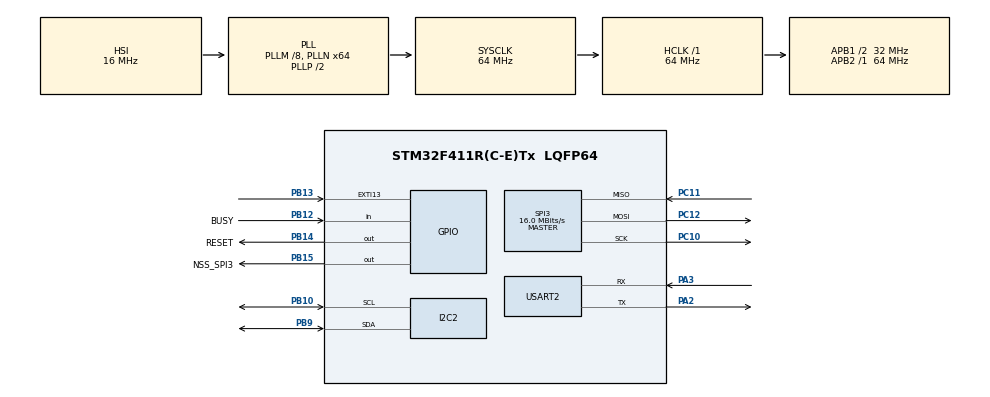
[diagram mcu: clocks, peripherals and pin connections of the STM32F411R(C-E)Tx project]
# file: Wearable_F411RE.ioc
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FREERTOS.Tasks01=defaultTask,24,128,StartDefaultTask,Default,NULL,Dynamic,NULL,NULL
FREERTOS.configENABLE_FPU=1
FREERTOS.configUSE_IDLE_HOOK=1
I2C2.OwnAddress=104
Mcu.Family=STM32F4
Mcu.Name=STM32F411R(C-E)Tx
Mcu.Package=LQFP64
NVIC.EXTI15_10_IRQn=true\:5\:0\:false\:false\:true\:true\:true\:true\:true
NVIC.PriorityGroup=NVIC_PRIORITYGROUP_4
NVIC.TIM2_IRQn=true\:15\:0\:false\:false\:true\:false\:false\:true\:true
NVIC.TimeBase=TIM2_IRQn
NVIC.TimeBaseIP=TIM2
PA13.GPIO_Label=TMS
PA13.Mode=Serial_Wire
PA13.Signal=SYS_JTMS-SWDIO
PA14.GPIO_Label=TCK
PA14.Mode=Serial_Wire
PA14.Signal=SYS_JTCK-SWCLK
PA2.Mode=Asynchronous
PA2.Signal=USART2_TX
PA3.Mode=Asynchronous
PA3.Signal=USART2_RX
PB10.Mode=I2C
PB10.Signal=I2C2_SCL
PB12.GPIO_Label=BUSY
PB12.Signal=GPIO_Input
PB13.Signal=GPXTI13
PB14.GPIO_Label=RESET
PB14.Signal=GPIO_Output
PB15.GPIO_Label=NSS_SPI3
PB15.Signal=GPIO_Output
PB3.GPIO_Label=SWO
PB3.Signal=SYS_JTDO-SWO
PB9.Mode=I2C
PB9.Signal=I2C2_SDA
PC10.Mode=Full_Duplex_Master
PC10.Signal=SPI3_SCK
PC11.Mode=Full_Duplex_Master
PC11.Signal=SPI3_MISO
PC12.Mode=Full_Duplex_Master
PC12.Signal=SPI3_MOSI
PC14-OSC32_IN.Mode=LSE-External-Oscillator
PC14-OSC32_IN.Signal=RCC_OSC32_IN
PC15-OSC32_OUT.Mode=LSE-External-Oscillator
PC15-OSC32_OUT.Signal=RCC_OSC32_OUT
PH0\ -\ OSC_IN.Mode=HSE-External-Oscillator
PH0\ -\ OSC_IN.Signal=RCC_OSC_IN
PH1\ -\ OSC_OUT.Mode=HSE-External-Oscillator
PH1\ -\ OSC_OUT.Signal=RCC_OSC_OUT
ProjectManager.HeapSize=0x200
ProjectManager.StackSize=0x400
ProjectManager.TargetToolchain=CMake
RCC.48MHZClocksFreq_Value=32000000
RCC.AHBFreq_Value=64000000
RCC.APB1CLKDivider=RCC_HCLK_DIV2
RCC.APB1Freq_Value=32000000
RCC.APB1TimFreq_Value=64000000
RCC.APB2Freq_Value=64000000
RCC.APB2TimFreq_Value=64000000
RCC.CortexFreq_Value=64000000
RCC.FLatency-AdvancedSettings=FLASH_LATENCY_2
RCC.HCLKFreq_Value=64000000
RCC.HSE_VALUE=8000000
RCC.HSI_VALUE=16000000
RCC.PLLM=8
RCC.PLLN=64
RCC.SYSCLKFreq_VALUE=64000000
RCC.SYSCLKSource=RCC_SYSCLKSOURCE_PLLCLK
RCC.VCOOutputFreq_Value=128000000
SPI3.CalculateBaudRate=16.0 MBits/s
SPI3.Direction=SPI_DIRECTION_2LINES
SPI3.Mode=SPI_MODE_MASTER
SPI3.VirtualType=VM_MASTER
TIM1.Prescaler=83
USART2.VirtualMode=VM_ASYNC
VP_FREERTOS_VS_CMSIS_V2.Mode=CMSIS_V2
VP_SYS_VS_tim2.Mode=TIM2
VP_TIM1_VS_ClockSourceINT.Mode=Internal
VP_TIM1_VS_ClockSourceITR.Mode=TriggerSource_ITR0
VP_TIM1_VS_ControllerModeReset.Mode=Reset Mode
board=NUCLEO-F411RE

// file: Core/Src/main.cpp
/* USER CODE BEGIN Header */
/**
 ******************************************************************************
 * @file           : main.c
 * @brief          : Main program body
 ******************************************************************************
 * @attention
 *
 * Copyright (c) 2025 STMicroelectronics.
 * All rights reserved.
 *
 * This software is licensed under terms that can be found in the LICENSE file
 * in the root directory of this software component.
 * If no LICENSE file comes with this software, it is provided AS-IS.
 *
 ******************************************************************************
 */
/* USER CODE END Header */
#include "main.h"
#include "cmsis_os.h"

/* USER CODE BEGIN Includes */
#include "RadioLib.h"
#include "SX1261.h"
#include "stm32RadioHal.h"
#include "LoRa.h"
#include "quaternion.h"
#include "compute_direction.h"
/* USER CODE END Includes */

I2C_HandleTypeDef hi2c2;

SPI_HandleTypeDef hspi3;

TIM_HandleTypeDef htim1;

UART_HandleTypeDef huart2;

/* Definitions for defaultTask */
osThreadId_t defaultTaskHandle;
const osThreadAttr_t defaultTask_attributes = {
    .name = "defaultTask",
    .stack_size = 128 * 4,
    .priority = (osPriority_t)osPriorityNormal,
};
/* USER CODE BEGIN PV */
SemaphoreHandle_t Transmit_receive_mutex = NULL;
/* USER CODE END PV */

void SystemClock_Config(void);
static void MX_GPIO_Init(void);
static void MX_SPI3_Init(void);
static void MX_I2C2_Init(void);
static void MX_TIM1_Init(void);
static void MX_USART2_UART_Init(void);
void StartDefaultTask(void *argument);

int main(void)
{

  /* MCU Configuration--------------------------------------------------------*/

  /* Reset of all peripherals, Initializes the Flash interface and the Systick. */
  HAL_Init();

  /* Configure the system clock */
  SystemClock_Config();

  /* Initialize all configured peripherals */
  MX_GPIO_Init();
  MX_SPI3_Init();
  MX_I2C2_Init();
  MX_TIM1_Init();
  MX_USART2_UART_Init();
  /* USER CODE BEGIN 2 */
  IMU_init();
  IMU_Calibrate_Accel_Gyro();
  IMU_Calibrate_Mag();
  set_yaw_offset();
  LoRa_Init();
  // Start the quaternion example task

  /* USER CODE END 2 */

  /* Init scheduler */
  osKernelInitialize();

  /* Create the thread(s) */
  /* creation of defaultTask */
  /* USER CODE BEGIN RTOS_THREADS */
  /* add threads, ... */
  xTaskCreate(LoRa_Calibrate_RSSI_rx, "LoRa_Calibrate_RSSI_rx", 512, NULL, 1, NULL);
  // xTaskCreate(LoRa_Calibrate_RSSI_tx, "LoRa_Calibrate_RSSI_tx", 512, NULL, 1, NULL);
  /* USER CODE END RTOS_THREADS */

  /* Start scheduler */
  osKernelStart();

  /* We should never get here as control is now taken by the scheduler */

  /* Infinite loop */
  while (1)
  {

  }
}

void SystemClock_Config(void)
{
  RCC_OscInitTypeDef RCC_OscInitStruct = {0};
  RCC_ClkInitTypeDef RCC_ClkInitStruct = {0};

  /** Configure the main internal regulator output voltage
   */
  __HAL_RCC_PWR_CLK_ENABLE();
  __HAL_PWR_VOLTAGESCALING_CONFIG(PWR_REGULATOR_VOLTAGE_SCALE1);

  /** Initializes the RCC Oscillators according to the specified parameters
   * in the RCC_OscInitTypeDef structure.
   */
  RCC_OscInitStruct.OscillatorType = RCC_OSCILLATORTYPE_HSI;
  RCC_OscInitStruct.HSIState = RCC_HSI_ON;
  RCC_OscInitStruct.HSICalibrationValue = RCC_HSICALIBRATION_DEFAULT;
  RCC_OscInitStruct.PLL.PLLState = RCC_PLL_ON;
  RCC_OscInitStruct.PLL.PLLSource = RCC_PLLSOURCE_HSI;
  RCC_OscInitStruct.PLL.PLLM = 8;
  RCC_OscInitStruct.PLL.PLLN = 64;
  RCC_OscInitStruct.PLL.PLLP = RCC_PLLP_DIV2;
  RCC_OscInitStruct.PLL.PLLQ = 4;
  if (HAL_RCC_OscConfig(&RCC_OscInitStruct) != HAL_OK)
  {
    Error_Handler();
  }

  /** Initializes the CPU, AHB and APB buses clocks
   */
  RCC_ClkInitStruct.ClockType = RCC_CLOCKTYPE_HCLK | RCC_CLOCKTYPE_SYSCLK | RCC_CLOCKTYPE_PCLK1 | RCC_CLOCKTYPE_PCLK2;
  RCC_ClkInitStruct.SYSCLKSource = RCC_SYSCLKSOURCE_PLLCLK;
  RCC_ClkInitStruct.AHBCLKDivider = RCC_SYSCLK_DIV1;
  RCC_ClkInitStruct.APB1CLKDivider = RCC_HCLK_DIV2;
  RCC_ClkInitStruct.APB2CLKDivider = RCC_HCLK_DIV1;

  if (HAL_RCC_ClockConfig(&RCC_ClkInitStruct, FLASH_LATENCY_2) != HAL_OK)
  {
    Error_Handler();
  }
}

static void MX_I2C2_Init(void)
{

  hi2c2.Instance = I2C2;
  hi2c2.Init.ClockSpeed = 100000;
  hi2c2.Init.DutyCycle = I2C_DUTYCYCLE_2;
  hi2c2.Init.OwnAddress1 = 208;
  hi2c2.Init.AddressingMode = I2C_ADDRESSINGMODE_7BIT;
  hi2c2.Init.DualAddressMode = I2C_DUALADDRESS_DISABLE;
  hi2c2.Init.OwnAddress2 = 0;
  hi2c2.Init.GeneralCallMode = I2C_GENERALCALL_DISABLE;
  hi2c2.Init.NoStretchMode = I2C_NOSTRETCH_DISABLE;
  if (HAL_I2C_Init(&hi2c2) != HAL_OK)
  {
    Error_Handler();
  }
}

static void MX_SPI3_Init(void)
{

  /* SPI3 parameter configuration*/
  hspi3.Instance = SPI3;
  hspi3.Init.Mode = SPI_MODE_MASTER;
  hspi3.Init.Direction = SPI_DIRECTION_2LINES;
  hspi3.Init.DataSize = SPI_DATASIZE_8BIT;
  hspi3.Init.CLKPolarity = SPI_POLARITY_LOW;
  hspi3.Init.CLKPhase = SPI_PHASE_1EDGE;
  hspi3.Init.NSS = SPI_NSS_SOFT;
  hspi3.Init.BaudRatePrescaler = SPI_BAUDRATEPRESCALER_2;
  hspi3.Init.FirstBit = SPI_FIRSTBIT_MSB;
  hspi3.Init.TIMode = SPI_TIMODE_DISABLE;
  hspi3.Init.CRCCalculation = SPI_CRCCALCULATION_DISABLE;
  hspi3.Init.CRCPolynomial = 10;
  if (HAL_SPI_Init(&hspi3) != HAL_OK)
  {
    Error_Handler();
  }
}

static void MX_TIM1_Init(void)
{

  TIM_ClockConfigTypeDef sClockSourceConfig = {0};
  TIM_SlaveConfigTypeDef sSlaveConfig = {0};
  TIM_MasterConfigTypeDef sMasterConfig = {0};

  htim1.Instance = TIM1;
  htim1.Init.Prescaler = 83;
  htim1.Init.CounterMode = TIM_COUNTERMODE_UP;
  htim1.Init.Period = 65535;
  htim1.Init.ClockDivision = TIM_CLOCKDIVISION_DIV1;
  htim1.Init.RepetitionCounter = 0;
  htim1.Init.AutoReloadPreload = TIM_AUTORELOAD_PRELOAD_DISABLE;
  if (HAL_TIM_Base_Init(&htim1) != HAL_OK)
  {
    Error_Handler();
  }
  sClockSourceConfig.ClockSource = TIM_CLOCKSOURCE_INTERNAL;
  if (HAL_TIM_ConfigClockSource(&htim1, &sClockSourceConfig) != HAL_OK)
  {
    Error_Handler();
  }
  sSlaveConfig.SlaveMode = TIM_SLAVEMODE_RESET;
  sSlaveConfig.InputTrigger = TIM_TS_ITR0;
  if (HAL_TIM_SlaveConfigSynchro(&htim1, &sSlaveConfig) != HAL_OK)
  {
    Error_Handler();
  }
  sMasterConfig.MasterOutputTrigger = TIM_TRGO_RESET;
  sMasterConfig.MasterSlaveMode = TIM_MASTERSLAVEMODE_DISABLE;
  if (HAL_TIMEx_MasterConfigSynchronization(&htim1, &sMasterConfig) != HAL_OK)
  {
    Error_Handler();
  }
}

static void MX_USART2_UART_Init(void)
{

  huart2.Instance = USART2;
  huart2.Init.BaudRate = 115200;
  huart2.Init.WordLength = UART_WORDLENGTH_8B;
  huart2.Init.StopBits = UART_STOPBITS_1;
  huart2.Init.Parity = UART_PARITY_NONE;
  huart2.Init.Mode = UART_MODE_TX_RX;
  huart2.Init.HwFlowCtl = UART_HWCONTROL_NONE;
  huart2.Init.OverSampling = UART_OVERSAMPLING_16;
  if (HAL_UART_Init(&huart2) != HAL_OK)
  {
    Error_Handler();
  }
}

static void MX_GPIO_Init(void)
{
  GPIO_InitTypeDef GPIO_InitStruct = {0};

  /* GPIO Ports Clock Enable */
  __HAL_RCC_GPIOC_CLK_ENABLE();
  __HAL_RCC_GPIOH_CLK_ENABLE();
  __HAL_RCC_GPIOA_CLK_ENABLE();
  __HAL_RCC_GPIOB_CLK_ENABLE();
  __HAL_RCC_GPIOD_CLK_ENABLE();

  /*Configure GPIO pin Output Level */
  HAL_GPIO_WritePin(GPIOB, RESET_Pin | NSS_SPI3_Pin, GPIO_PIN_RESET);

  /*Configure GPIO pins : PC13 PC0 PC1 PC2
                           PC3 PC4 PC5 PC6
                           PC7 PC8 PC9 */
  GPIO_InitStruct.Pin = GPIO_PIN_13 | GPIO_PIN_0 | GPIO_PIN_1 | GPIO_PIN_2 | GPIO_PIN_3 | GPIO_PIN_4 | GPIO_PIN_5 | GPIO_PIN_6 | GPIO_PIN_7 | GPIO_PIN_8 | GPIO_PIN_9;
  GPIO_InitStruct.Mode = GPIO_MODE_ANALOG;
  GPIO_InitStruct.Pull = GPIO_NOPULL;
  HAL_GPIO_Init(GPIOC, &GPIO_InitStruct);

  /*Configure GPIO pins : PA0 PA1 PA4 PA5
                           PA6 PA7 PA8 PA9
                           PA10 PA11 PA12 PA15 */
  GPIO_InitStruct.Pin = GPIO_PIN_0 | GPIO_PIN_1 | GPIO_PIN_4 | GPIO_PIN_5 | GPIO_PIN_6 | GPIO_PIN_7 | GPIO_PIN_8 | GPIO_PIN_9 | GPIO_PIN_10 | GPIO_PIN_11 | GPIO_PIN_12 | GPIO_PIN_15;
  GPIO_InitStruct.Mode = GPIO_MODE_ANALOG;
  GPIO_InitStruct.Pull = GPIO_NOPULL;
  HAL_GPIO_Init(GPIOA, &GPIO_InitStruct);

  /*Configure GPIO pins : PB0 PB1 PB2 PB4
                           PB5 PB6 PB7 PB8 */
  GPIO_InitStruct.Pin = GPIO_PIN_0 | GPIO_PIN_1 | GPIO_PIN_2 | GPIO_PIN_4 | GPIO_PIN_5 | GPIO_PIN_6 | GPIO_PIN_7 | GPIO_PIN_8;
  GPIO_InitStruct.Mode = GPIO_MODE_ANALOG;
  GPIO_InitStruct.Pull = GPIO_NOPULL;
  HAL_GPIO_Init(GPIOB, &GPIO_InitStruct);

  /*Configure GPIO pin : BUSY_Pin */
  GPIO_InitStruct.Pin = BUSY_Pin;
  GPIO_InitStruct.Mode = GPIO_MODE_INPUT;
  GPIO_InitStruct.Pull = GPIO_NOPULL;
  HAL_GPIO_Init(BUSY_GPIO_Port, &GPIO_InitStruct);

  /*Configure GPIO pin : PB13 */
  GPIO_InitStruct.Pin = GPIO_PIN_13;
  GPIO_InitStruct.Mode = GPIO_MODE_IT_RISING;
  GPIO_InitStruct.Pull = GPIO_NOPULL;
  HAL_GPIO_Init(GPIOB, &GPIO_InitStruct);

  /*Configure GPIO pins : RESET_Pin NSS_SPI3_Pin */
  GPIO_InitStruct.Pin = RESET_Pin | NSS_SPI3_Pin;
  GPIO_InitStruct.Mode = GPIO_MODE_OUTPUT_PP;
  GPIO_InitStruct.Pull = GPIO_NOPULL;
  GPIO_InitStruct.Speed = GPIO_SPEED_FREQ_LOW;
  HAL_GPIO_Init(GPIOB, &GPIO_InitStruct);

  /*Configure GPIO pin : PD2 */
  GPIO_InitStruct.Pin = GPIO_PIN_2;
  GPIO_InitStruct.Mode = GPIO_MODE_ANALOG;
  GPIO_InitStruct.Pull = GPIO_NOPULL;
  HAL_GPIO_Init(GPIOD, &GPIO_InitStruct);

  /* EXTI interrupt init*/
  HAL_NVIC_SetPriority(EXTI15_10_IRQn, 5, 0);
  HAL_NVIC_EnableIRQ(EXTI15_10_IRQn);

}

void StartDefaultTask(void *argument)
{
  for (;;)
  {
    osDelay(1);
  }
}

void HAL_TIM_PeriodElapsedCallback(TIM_HandleTypeDef *htim)
{
  if (htim->Instance == TIM2)
  {
    HAL_IncTick();
  }
}

void Error_Handler(void)
{
  __disable_irq();
  while (1)
  {
  }
}

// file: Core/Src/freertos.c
/* USER CODE BEGIN Header */
/**
  ******************************************************************************
  * File Name          : freertos.c
  * Description        : Code for freertos applications
  ******************************************************************************
  * @attention
  *
  * Copyright (c) 2025 STMicroelectronics.
  * All rights reserved.
  *
  * This software is licensed under terms that can be found in the LICENSE file
  * in the root directory of this software component.
  * If no LICENSE file comes with this software, it is provided AS-IS.
  *
  ******************************************************************************
  */
/* USER CODE END Header */

#include "FreeRTOS.h"
#include "task.h"
#include "main.h"

/* Hook prototypes */
void vApplicationIdleHook(void);

/* USER CODE BEGIN 2 */
void vApplicationIdleHook( void )
{
   /* vApplicationIdleHook() will only be called if configUSE_IDLE_HOOK is set
   to 1 in FreeRTOSConfig.h. It will be called on each iteration of the idle
   task. It is essential that code added to this hook function never attempts
   to block in any way (for example, call xQueueReceive() with a block time
   specified, or call vTaskDelay()). If the application makes use of the
   vTaskDelete() API function (as this demo application does) then it is also
   important that vApplicationIdleHook() is permitted to return to its calling
   function, because it is the responsibility of the idle task to clean up
   memory allocated by the kernel to any task that has since been deleted. */
}
/* USER CODE END 2 */
